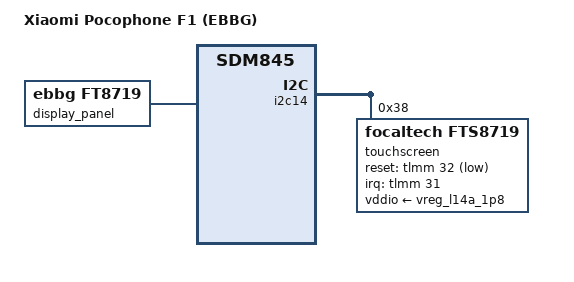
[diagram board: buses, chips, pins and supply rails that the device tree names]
// SPDX-License-Identifier: GPL-2.0

/dts-v1/;

#include "sdm845-xiaomi-beryllium-common.dtsi"

/ {
	model = "Xiaomi Pocophone F1 (EBBG)";
	compatible = "xiaomi,beryllium-ebbg", "qcom,sdm845";
};

&display_panel {
	compatible = "ebbg,ft8719";
	status = "okay";
};

&i2c14 {
	status = "okay";

	dmas =  <&gpi_dma1 0 6 QCOM_GPI_I2C>,
		<&gpi_dma1 1 6 QCOM_GPI_I2C>;
	dma-names = "tx", "rx";

	touchscreen: focaltech@38 {
		compatible = "focaltech,fts8719";
		reg = <0x38>;
		interrupt-parent = <&tlmm>;
		interrupts = <31 IRQ_TYPE_EDGE_RISING>;

		vddio-supply = <&vreg_l14a_1p8>;

		pinctrl-names = "default", "sleep";
		pinctrl-0 = <&ts_int_default &ts_reset_default>;
		pinctrl-1 = <&ts_int_sleep &ts_reset_sleep>;

		reset-gpios = <&tlmm 32 GPIO_ACTIVE_LOW>;

		touchscreen-size-x = <1080>;
		touchscreen-size-y = <2246>;
		focaltech,max-touch-number = <10>;
	};
};
